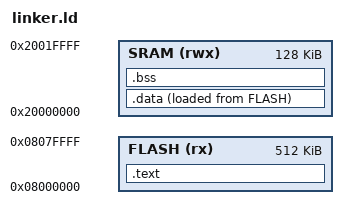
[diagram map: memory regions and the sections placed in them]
MEMORY
{
    FLASH (rx) : ORIGIN = 0x08000000, LENGTH = 512K
    SRAM (rwx) : ORIGIN = 0x20000000, LENGTH = 128K
}

ENTRY(_start)

SECTIONS
{
    .text : {
        . = ALIGN(4);
        *(.text .text.*);
        *(.rodata .rodata.*);
        . = ALIGN(4);
        _etext = .;
    } > FLASH

    .data : {
        _sdata = .;
        *(.data);
        _edata = .;
    } > SRAM AT > FLASH

    .bss : {
        _sbss = .;
        *(.bss .bss.*);
        *(COMMON);
        _ebss = .;
    } > SRAM
}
